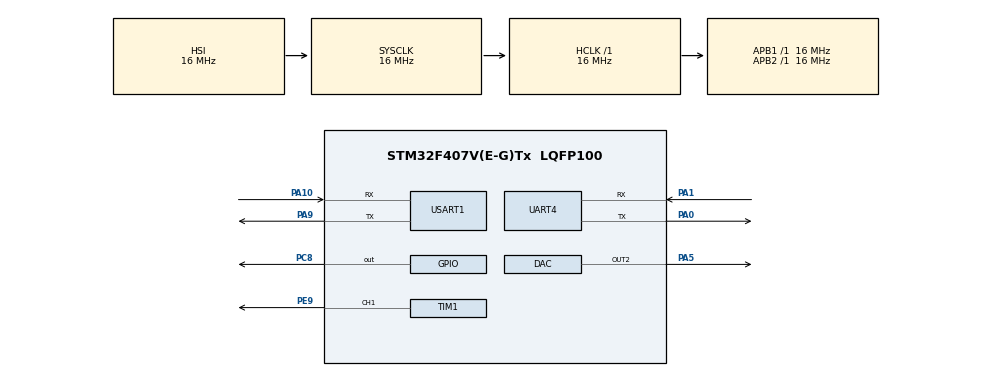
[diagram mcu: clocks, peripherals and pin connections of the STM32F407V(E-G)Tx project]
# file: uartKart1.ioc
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Mcu.Family=STM32F4
PH0-OSC_IN.Signal=RCC_OSC_IN
RCC.CortexFreq_Value=16000000
PA10.Mode=Asynchronous
PC8.Signal=GPIO_Output
UART4.VirtualMode=Asynchronous
ProjectManager.StackSize=0x400
PA0-WKUP.Signal=UART4_TX
SH.COMP_DAC2_group.0=DAC_OUT2,DAC_OUT2
PA0-WKUP.Mode=Asynchronous
PA13.Signal=SYS_JTMS-SWDIO
PA9.Mode=Asynchronous
SH.S_TIM1_CH1.0=TIM1_CH1,PWM Generation1 CH1
ProjectManager.TargetToolchain=STM32CubeIDE
PA9.Signal=USART1_TX
RCC.LSE_VALUE=32768
PA1.Signal=UART4_RX
RCC.AHBFreq_Value=16000000
PH0-OSC_IN.Mode=HSE-External-Oscillator
PA5.Signal=COMP_DAC2_group
RCC.HSE_VALUE=25000000
board=custom
RCC.VCOOutputFreq_Value=192000000
RCC.APB2Freq_Value=16000000
PA1.Mode=Asynchronous
TIM1.Channel-PWM\ Generation1\ CH1=TIM_CHANNEL_1
PE9.Signal=S_TIM1_CH1
PA14.Mode=Serial_Wire
PH1-OSC_OUT.Signal=RCC_OSC_OUT
PA13.Mode=Serial_Wire
Mcu.Name=STM32F407V(E-G)Tx
PH1-OSC_OUT.Mode=HSE-External-Oscillator
RCC.SYSCLKFreq_VALUE=16000000
Mcu.Package=LQFP100
USART1.VirtualMode=VM_ASYNC
PA10.Signal=USART1_RX
PA14.Signal=SYS_JTCK-SWCLK
ProjectManager.HeapSize=0x200
RCC.HSI_VALUE=16000000
NVIC.PriorityGroup=NVIC_PRIORITYGROUP_4
RCC.APB1Freq_Value=16000000

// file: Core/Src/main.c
/* USER CODE BEGIN Header */
/**
 ******************************************************************************
 * @file           : main.c
 * @brief          : Main program body
 ******************************************************************************
 * @attention
 *
 * <h2><center>&copy; Copyright (c) 2020 STMicroelectronics.
 * All rights reserved.</center></h2>
 *
 * This software component is licensed by ST under BSD 3-Clause license,
 * the "License"; You may not use this file except in compliance with the
 * License. You may obtain a copy of the License at:
 *                        opensource.org/licenses/BSD-3-Clause
 *
 ******************************************************************************
 */
/* USER CODE END Header */
#include "main.h"

DAC_HandleTypeDef hdac;

TIM_HandleTypeDef htim1;

UART_HandleTypeDef huart4;
UART_HandleTypeDef huart1;

/* USER CODE BEGIN PV */
uint8_t al,gonder=1;
/* USER CODE END PV */

void SystemClock_Config(void);
static void MX_GPIO_Init(void);
static void MX_UART4_Init(void);
static void MX_DAC_Init(void);
static void MX_TIM1_Init(void);
static void MX_USART1_UART_Init(void);

int main(void)
{

	/* MCU Configuration--------------------------------------------------------*/

	/* Reset of all peripherals, Initializes the Flash interface and the Systick. */
	HAL_Init();

	/* Configure the system clock */
	SystemClock_Config();

	/* Initialize all configured peripherals */
	MX_GPIO_Init();
	MX_UART4_Init();
	MX_DAC_Init();
	MX_TIM1_Init();
	MX_USART1_UART_Init();

	/* Infinite loop */
	/* USER CODE BEGIN WHILE */
	while (1)
	{
		HAL_UART_Transmit(&huart4, &gonder, sizeof(gonder), 1000);
		HAL_UART_Receive(&huart4, &al, sizeof(al), 1000);
		if (gonder >= 100)
		{
			gonder=1;
		}
		else
		{
			gonder=al;
		}
		al=0;
		HAL_Delay(1000);
		/* USER CODE END WHILE */

	}
}

void SystemClock_Config(void)
{
	RCC_OscInitTypeDef RCC_OscInitStruct = {0};
	RCC_ClkInitTypeDef RCC_ClkInitStruct = {0};

	/** Configure the main internal regulator output voltage
	 */
	__HAL_RCC_PWR_CLK_ENABLE();
	__HAL_PWR_VOLTAGESCALING_CONFIG(PWR_REGULATOR_VOLTAGE_SCALE1);
	/** Initializes the RCC Oscillators according to the specified parameters
	 * in the RCC_OscInitTypeDef structure.
	 */
	RCC_OscInitStruct.OscillatorType = RCC_OSCILLATORTYPE_HSI;
	RCC_OscInitStruct.HSIState = RCC_HSI_ON;
	RCC_OscInitStruct.HSICalibrationValue = RCC_HSICALIBRATION_DEFAULT;
	RCC_OscInitStruct.PLL.PLLState = RCC_PLL_NONE;
	if (HAL_RCC_OscConfig(&RCC_OscInitStruct) != HAL_OK)
	{
		Error_Handler();
	}
	/** Initializes the CPU, AHB and APB buses clocks
	 */
	RCC_ClkInitStruct.ClockType = RCC_CLOCKTYPE_HCLK|RCC_CLOCKTYPE_SYSCLK
			|RCC_CLOCKTYPE_PCLK1|RCC_CLOCKTYPE_PCLK2;
	RCC_ClkInitStruct.SYSCLKSource = RCC_SYSCLKSOURCE_HSI;
	RCC_ClkInitStruct.AHBCLKDivider = RCC_SYSCLK_DIV1;
	RCC_ClkInitStruct.APB1CLKDivider = RCC_HCLK_DIV1;
	RCC_ClkInitStruct.APB2CLKDivider = RCC_HCLK_DIV1;

	if (HAL_RCC_ClockConfig(&RCC_ClkInitStruct, FLASH_LATENCY_0) != HAL_OK)
	{
		Error_Handler();
	}
}

static void MX_DAC_Init(void)
{

	DAC_ChannelConfTypeDef sConfig = {0};

	/** DAC Initialization
	 */
	hdac.Instance = DAC;
	if (HAL_DAC_Init(&hdac) != HAL_OK)
	{
		Error_Handler();
	}
	/** DAC channel OUT2 config
	 */
	sConfig.DAC_Trigger = DAC_TRIGGER_NONE;
	sConfig.DAC_OutputBuffer = DAC_OUTPUTBUFFER_ENABLE;
	if (HAL_DAC_ConfigChannel(&hdac, &sConfig, DAC_CHANNEL_2) != HAL_OK)
	{
		Error_Handler();
	}

}

static void MX_TIM1_Init(void)
{

	TIM_MasterConfigTypeDef sMasterConfig = {0};
	TIM_OC_InitTypeDef sConfigOC = {0};
	TIM_BreakDeadTimeConfigTypeDef sBreakDeadTimeConfig = {0};

	htim1.Instance = TIM1;
	htim1.Init.Prescaler = 0;
	htim1.Init.CounterMode = TIM_COUNTERMODE_UP;
	htim1.Init.Period = 65535;
	htim1.Init.ClockDivision = TIM_CLOCKDIVISION_DIV1;
	htim1.Init.RepetitionCounter = 0;
	htim1.Init.AutoReloadPreload = TIM_AUTORELOAD_PRELOAD_DISABLE;
	if (HAL_TIM_PWM_Init(&htim1) != HAL_OK)
	{
		Error_Handler();
	}
	sMasterConfig.MasterOutputTrigger = TIM_TRGO_RESET;
	sMasterConfig.MasterSlaveMode = TIM_MASTERSLAVEMODE_DISABLE;
	if (HAL_TIMEx_MasterConfigSynchronization(&htim1, &sMasterConfig) != HAL_OK)
	{
		Error_Handler();
	}
	sConfigOC.OCMode = TIM_OCMODE_PWM1;
	sConfigOC.Pulse = 0;
	sConfigOC.OCPolarity = TIM_OCPOLARITY_HIGH;
	sConfigOC.OCNPolarity = TIM_OCNPOLARITY_HIGH;
	sConfigOC.OCFastMode = TIM_OCFAST_DISABLE;
	sConfigOC.OCIdleState = TIM_OCIDLESTATE_RESET;
	sConfigOC.OCNIdleState = TIM_OCNIDLESTATE_RESET;
	if (HAL_TIM_PWM_ConfigChannel(&htim1, &sConfigOC, TIM_CHANNEL_1) != HAL_OK)
	{
		Error_Handler();
	}
	sBreakDeadTimeConfig.OffStateRunMode = TIM_OSSR_DISABLE;
	sBreakDeadTimeConfig.OffStateIDLEMode = TIM_OSSI_DISABLE;
	sBreakDeadTimeConfig.LockLevel = TIM_LOCKLEVEL_OFF;
	sBreakDeadTimeConfig.DeadTime = 0;
	sBreakDeadTimeConfig.BreakState = TIM_BREAK_DISABLE;
	sBreakDeadTimeConfig.BreakPolarity = TIM_BREAKPOLARITY_HIGH;
	sBreakDeadTimeConfig.AutomaticOutput = TIM_AUTOMATICOUTPUT_DISABLE;
	if (HAL_TIMEx_ConfigBreakDeadTime(&htim1, &sBreakDeadTimeConfig) != HAL_OK)
	{
		Error_Handler();
	}
	HAL_TIM_MspPostInit(&htim1);

}

static void MX_UART4_Init(void)
{

	huart4.Instance = UART4;
	huart4.Init.BaudRate = 115200;
	huart4.Init.WordLength = UART_WORDLENGTH_8B;
	huart4.Init.StopBits = UART_STOPBITS_1;
	huart4.Init.Parity = UART_PARITY_NONE;
	huart4.Init.Mode = UART_MODE_TX_RX;
	huart4.Init.HwFlowCtl = UART_HWCONTROL_NONE;
	huart4.Init.OverSampling = UART_OVERSAMPLING_16;
	if (HAL_UART_Init(&huart4) != HAL_OK)
	{
		Error_Handler();
	}

}

static void MX_USART1_UART_Init(void)
{

	huart1.Instance = USART1;
	huart1.Init.BaudRate = 115200;
	huart1.Init.WordLength = UART_WORDLENGTH_8B;
	huart1.Init.StopBits = UART_STOPBITS_1;
	huart1.Init.Parity = UART_PARITY_NONE;
	huart1.Init.Mode = UART_MODE_TX_RX;
	huart1.Init.HwFlowCtl = UART_HWCONTROL_NONE;
	huart1.Init.OverSampling = UART_OVERSAMPLING_16;
	if (HAL_UART_Init(&huart1) != HAL_OK)
	{
		Error_Handler();
	}

}

static void MX_GPIO_Init(void)
{
	GPIO_InitTypeDef GPIO_InitStruct = {0};

	/* GPIO Ports Clock Enable */
	__HAL_RCC_GPIOH_CLK_ENABLE();
	__HAL_RCC_GPIOA_CLK_ENABLE();
	__HAL_RCC_GPIOE_CLK_ENABLE();
	__HAL_RCC_GPIOC_CLK_ENABLE();

	/*Configure GPIO pin Output Level */
	HAL_GPIO_WritePin(GPIOC, GPIO_PIN_8, GPIO_PIN_RESET);

	/*Configure GPIO pin : PC8 */
	GPIO_InitStruct.Pin = GPIO_PIN_8;
	GPIO_InitStruct.Mode = GPIO_MODE_OUTPUT_PP;
	GPIO_InitStruct.Pull = GPIO_NOPULL;
	GPIO_InitStruct.Speed = GPIO_SPEED_FREQ_LOW;
	HAL_GPIO_Init(GPIOC, &GPIO_InitStruct);

}

void Error_Handler(void)
{
	__disable_irq();
	while (1)
	{
	}
}

/************************ (C) COPYRIGHT STMicroelectronics *****END OF FILE****/
